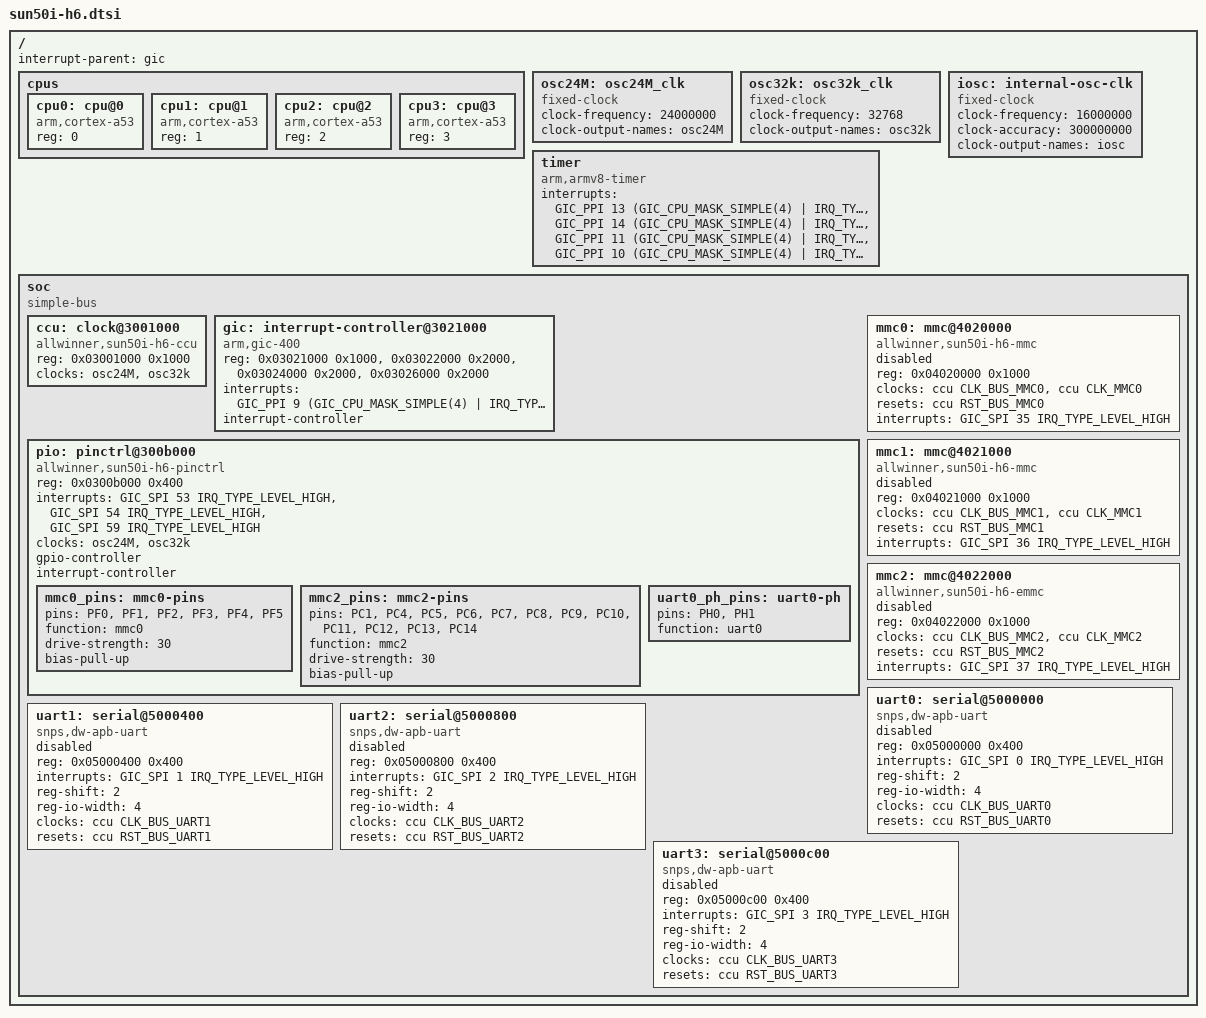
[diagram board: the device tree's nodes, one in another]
/*
 * Copyright (C) 2017 Icenowy Zheng <icenowy@aosc.io>
 *
 * This file is dual-licensed: you can use it either under the terms
 * of the GPL or the X11 license, at your option. Note that this dual
 * licensing only applies to this file, and not this project as a
 * whole.
 *
 *  a) This file is free software; you can redistribute it and/or
 *     modify it under the terms of the GNU General Public License as
 *     published by the Free Software Foundation; either version 2 of the
 *     License, or (at your option) any later version.
 *
 *     This file is distributed in the hope that it will be useful,
 *     but WITHOUT ANY WARRANTY; without even the implied warranty of
 *     MERCHANTABILITY or FITNESS FOR A PARTICULAR PURPOSE.  See the
 *     GNU General Public License for more details.
 *
 * Or, alternatively,
 *
 *  b) Permission is hereby granted, free of charge, to any person
 *     obtaining a copy of this software and associated documentation
 *     files (the "Software"), to deal in the Software without
 *     restriction, including without limitation the rights to use,
 *     copy, modify, merge, publish, distribute, sublicense, and/or
 *     sell copies of the Software, and to permit persons to whom the
 *     Software is furnished to do so, subject to the following
 *     conditions:
 *
 *     The above copyright notice and this permission notice shall be
 *     included in all copies or substantial portions of the Software.
 *
 *     THE SOFTWARE IS PROVIDED "AS IS", WITHOUT WARRANTY OF ANY KIND,
 *     EXPRESS OR IMPLIED, INCLUDING BUT NOT LIMITED TO THE WARRANTIES
 *     OF MERCHANTABILITY, FITNESS FOR A PARTICULAR PURPOSE AND
 *     NONINFRINGEMENT. IN NO EVENT SHALL THE AUTHORS OR COPYRIGHT
 *     HOLDERS BE LIABLE FOR ANY CLAIM, DAMAGES OR OTHER LIABILITY,
 *     WHETHER IN AN ACTION OF CONTRACT, TORT OR OTHERWISE, ARISING
 *     FROM, OUT OF OR IN CONNECTION WITH THE SOFTWARE OR THE USE OR
 *     OTHER DEALINGS IN THE SOFTWARE.
 */

#include <dt-bindings/interrupt-controller/arm-gic.h>
#include <dt-bindings/clock/sun50i-h6-ccu.h>
#include <dt-bindings/reset/sun50i-h6-ccu.h>

/ {
	interrupt-parent = <&gic>;
	#address-cells = <1>;
	#size-cells = <1>;

	cpus {
		#address-cells = <1>;
		#size-cells = <0>;

		cpu0: cpu@0 {
			compatible = "arm,cortex-a53", "arm,armv8";
			device_type = "cpu";
			reg = <0>;
		};

		cpu1: cpu@1 {
			compatible = "arm,cortex-a53", "arm,armv8";
			device_type = "cpu";
			reg = <1>;
		};

		cpu2: cpu@2 {
			compatible = "arm,cortex-a53", "arm,armv8";
			device_type = "cpu";
			reg = <2>;
		};

		cpu3: cpu@3 {
			compatible = "arm,cortex-a53", "arm,armv8";
			device_type = "cpu";
			reg = <3>;
		};
	};

	osc24M: osc24M_clk {
		#clock-cells = <0>;
		compatible = "fixed-clock";
		clock-frequency = <24000000>;
		clock-output-names = "osc24M";
	};

	osc32k: osc32k_clk {
		#clock-cells = <0>;
		compatible = "fixed-clock";
		clock-frequency = <32768>;
		clock-output-names = "osc32k";
	};

	iosc: internal-osc-clk {
		#clock-cells = <0>;
		compatible = "fixed-clock";
		clock-frequency = <16000000>;
		clock-accuracy = <300000000>;
		clock-output-names = "iosc";
	};

	timer {
		compatible = "arm,armv8-timer";
		interrupts = <GIC_PPI 13
			(GIC_CPU_MASK_SIMPLE(4) | IRQ_TYPE_LEVEL_HIGH)>,
			     <GIC_PPI 14
			(GIC_CPU_MASK_SIMPLE(4) | IRQ_TYPE_LEVEL_HIGH)>,
			     <GIC_PPI 11
			(GIC_CPU_MASK_SIMPLE(4) | IRQ_TYPE_LEVEL_HIGH)>,
			     <GIC_PPI 10
			(GIC_CPU_MASK_SIMPLE(4) | IRQ_TYPE_LEVEL_HIGH)>;
	};

	soc {
		compatible = "simple-bus";
		#address-cells = <1>;
		#size-cells = <1>;
		ranges;

		ccu: clock@3001000 {
			compatible = "allwinner,sun50i-h6-ccu";
			reg = <0x03001000 0x1000>;
			clocks = <&osc24M>, <&osc32k>;
			clock-names = "hosc", "losc";
			#clock-cells = <1>;
			#reset-cells = <1>;
		};

		gic: interrupt-controller@3021000 {
			compatible = "arm,gic-400";
			reg = <0x03021000 0x1000>,
			      <0x03022000 0x2000>,
			      <0x03024000 0x2000>,
			      <0x03026000 0x2000>;
			interrupts = <GIC_PPI 9 (GIC_CPU_MASK_SIMPLE(4) | IRQ_TYPE_LEVEL_HIGH)>;
			interrupt-controller;
			#interrupt-cells = <3>;
		};

		pio: pinctrl@300b000 {
			compatible = "allwinner,sun50i-h6-pinctrl";
			reg = <0x0300b000 0x400>;
			interrupts = <GIC_SPI 53 IRQ_TYPE_LEVEL_HIGH>,
				     <GIC_SPI 54 IRQ_TYPE_LEVEL_HIGH>,
				     <GIC_SPI 59 IRQ_TYPE_LEVEL_HIGH>;
			clocks = <&osc24M>, <&osc32k>;
			clock-names = "hosc", "losc";
			gpio-controller;
			#gpio-cells = <3>;
			interrupt-controller;
			#interrupt-cells = <3>;

			mmc0_pins: mmc0-pins {
				pins = "PF0", "PF1", "PF2", "PF3",
				       "PF4", "PF5";
				function = "mmc0";
				drive-strength = <30>;
				bias-pull-up;
			};

			mmc2_pins: mmc2-pins {
				pins = "PC1", "PC4", "PC5", "PC6",
				       "PC7", "PC8", "PC9", "PC10",
				       "PC11", "PC12", "PC13", "PC14";
				function = "mmc2";
				drive-strength = <30>;
				bias-pull-up;
			};

			uart0_ph_pins: uart0-ph {
				pins = "PH0", "PH1";
				function = "uart0";
			};
		};

		mmc0: mmc@4020000 {
			compatible = "allwinner,sun50i-h6-mmc";
			reg = <0x04020000 0x1000>;
			clocks = <&ccu CLK_BUS_MMC0>, <&ccu CLK_MMC0>;
			clock-names = "ahb", "mmc";
			resets = <&ccu RST_BUS_MMC0>;
			reset-names = "ahb";
			interrupts = <GIC_SPI 35 IRQ_TYPE_LEVEL_HIGH>;
			status = "disabled";
			#address-cells = <1>;
			#size-cells = <0>;
		};

		mmc1: mmc@4021000 {
			compatible = "allwinner,sun50i-h6-mmc";
			reg = <0x04021000 0x1000>;
			clocks = <&ccu CLK_BUS_MMC1>, <&ccu CLK_MMC1>;
			clock-names = "ahb", "mmc";
			resets = <&ccu RST_BUS_MMC1>;
			reset-names = "ahb";
			interrupts = <GIC_SPI 36 IRQ_TYPE_LEVEL_HIGH>;
			status = "disabled";
			#address-cells = <1>;
			#size-cells = <0>;
		};

		mmc2: mmc@4022000 {
			compatible = "allwinner,sun50i-h6-emmc";
			reg = <0x04022000 0x1000>;
			clocks = <&ccu CLK_BUS_MMC2>, <&ccu CLK_MMC2>;
			clock-names = "ahb", "mmc";
			resets = <&ccu RST_BUS_MMC2>;
			reset-names = "ahb";
			interrupts = <GIC_SPI 37 IRQ_TYPE_LEVEL_HIGH>;
			status = "disabled";
			#address-cells = <1>;
			#size-cells = <0>;
		};

		uart0: serial@5000000 {
			compatible = "snps,dw-apb-uart";
			reg = <0x05000000 0x400>;
			interrupts = <GIC_SPI 0 IRQ_TYPE_LEVEL_HIGH>;
			reg-shift = <2>;
			reg-io-width = <4>;
			clocks = <&ccu CLK_BUS_UART0>;
			resets = <&ccu RST_BUS_UART0>;
			status = "disabled";
		};

		uart1: serial@5000400 {
			compatible = "snps,dw-apb-uart";
			reg = <0x05000400 0x400>;
			interrupts = <GIC_SPI 1 IRQ_TYPE_LEVEL_HIGH>;
			reg-shift = <2>;
			reg-io-width = <4>;
			clocks = <&ccu CLK_BUS_UART1>;
			resets = <&ccu RST_BUS_UART1>;
			status = "disabled";
		};

		uart2: serial@5000800 {
			compatible = "snps,dw-apb-uart";
			reg = <0x05000800 0x400>;
			interrupts = <GIC_SPI 2 IRQ_TYPE_LEVEL_HIGH>;
			reg-shift = <2>;
			reg-io-width = <4>;
			clocks = <&ccu CLK_BUS_UART2>;
			resets = <&ccu RST_BUS_UART2>;
			status = "disabled";
		};

		uart3: serial@5000c00 {
			compatible = "snps,dw-apb-uart";
			reg = <0x05000c00 0x400>;
			interrupts = <GIC_SPI 3 IRQ_TYPE_LEVEL_HIGH>;
			reg-shift = <2>;
			reg-io-width = <4>;
			clocks = <&ccu CLK_BUS_UART3>;
			resets = <&ccu RST_BUS_UART3>;
			status = "disabled";
		};
	};
};
